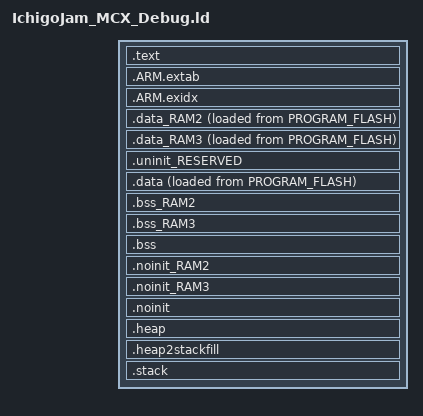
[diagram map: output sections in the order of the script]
/*
 * GENERATED FILE - DO NOT EDIT
 * Copyright 2008-2013 Code Red Technologies Ltd,
 * Copyright 2013-2025 NXP
 * SPDX-License-Identifier: BSD-3-Clause
 * Generated linker script file for MCXA153
 * Created from linkscript.ldt by FMCreateLinkLibraries
 * Using Freemarker v2.3.30
 * MCUXpresso IDE v24.12 [Build 148] [2025-01-10] on 2025/04/03 16:53:05
 */

INCLUDE "IchigoJam_MCX_Debug_library.ld"
INCLUDE "IchigoJam_MCX_Debug_memory.ld"

ENTRY(ResetISR)

SECTIONS
{
     /* MAIN TEXT SECTION */
    .text : ALIGN(4)
    {
        FILL(0xff)
        __vectors_start__ = ABSOLUTE(.) ;
        KEEP(*(.isr_vector))
        /* Global Section Table */
        . = ALIGN(4) ;
        __section_table_start = .;
        __data_section_table = .;
        LONG(LOADADDR(.data));
        LONG(    ADDR(.data));
        LONG(  SIZEOF(.data));
        LONG(LOADADDR(.data_RAM2));
        LONG(    ADDR(.data_RAM2));
        LONG(  SIZEOF(.data_RAM2));
        LONG(LOADADDR(.data_RAM3));
        LONG(    ADDR(.data_RAM3));
        LONG(  SIZEOF(.data_RAM3));
        __data_section_table_end = .;
        __bss_section_table = .;
        LONG(    ADDR(.bss));
        LONG(  SIZEOF(.bss));
        LONG(    ADDR(.bss_RAM2));
        LONG(  SIZEOF(.bss_RAM2));
        LONG(    ADDR(.bss_RAM3));
        LONG(  SIZEOF(.bss_RAM3));
        __bss_section_table_end = .;
        __section_table_end = . ;
        /* End of Global Section Table */

        *(.after_vectors*)

       *(.text*)
       *(.rodata .rodata.* .constdata .constdata.*)
       . = ALIGN(4);
    } > PROGRAM_FLASH
    /*
     * for exception handling/unwind - some Newlib functions (in common
     * with C++ and STDC++) use this.
     */
    .ARM.extab : ALIGN(4)
    {
        *(.ARM.extab* .gnu.linkonce.armextab.*)
    } > PROGRAM_FLASH

    .ARM.exidx : ALIGN(4)
    {
        __exidx_start = .;
        *(.ARM.exidx* .gnu.linkonce.armexidx.*)
        __exidx_end = .;
    } > PROGRAM_FLASH
 
    _etext = .;
        
    /* DATA section for SRAMX0 */

    .data_RAM2 : ALIGN(4)
    {
        FILL(0xff)
        PROVIDE(__start_data_RAM2 = .) ;
        PROVIDE(__start_data_SRAMX0 = .) ;
        *(.ramfunc.$RAM2)
        *(.ramfunc.$SRAMX0)
        *(.data.$RAM2)
        *(.data.$SRAMX0)
        *(.data.$RAM2.*)
        *(.data.$SRAMX0.*)
        . = ALIGN(4) ;
        PROVIDE(__end_data_RAM2 = .) ;
        PROVIDE(__end_data_SRAMX0 = .) ;
     } > SRAMX0 AT>PROGRAM_FLASH

    /* DATA section for SRAMX1 */

    .data_RAM3 : ALIGN(4)
    {
        FILL(0xff)
        PROVIDE(__start_data_RAM3 = .) ;
        PROVIDE(__start_data_SRAMX1 = .) ;
        *(.ramfunc.$RAM3)
        *(.ramfunc.$SRAMX1)
        *(.data.$RAM3)
        *(.data.$SRAMX1)
        *(.data.$RAM3.*)
        *(.data.$SRAMX1.*)
        . = ALIGN(4) ;
        PROVIDE(__end_data_RAM3 = .) ;
        PROVIDE(__end_data_SRAMX1 = .) ;
     } > SRAMX1 AT>PROGRAM_FLASH

    /* MAIN DATA SECTION */
    .uninit_RESERVED (NOLOAD) : ALIGN(4)
    {
        _start_uninit_RESERVED = .;
        KEEP(*(.bss.$RESERVED*))
       . = ALIGN(4) ;
        _end_uninit_RESERVED = .;
    } > SRAM AT> SRAM

    /* Main DATA section (SRAM) */
    .data : ALIGN(4)
    {
       FILL(0xff)
       _data = . ;
       PROVIDE(__start_data_RAM = .) ;
       PROVIDE(__start_data_SRAM = .) ;
       *(vtable)
       *(.ramfunc*)
       KEEP(*(CodeQuickAccess))
       KEEP(*(DataQuickAccess))
       *(RamFunction)
       *(.data*)
       . = ALIGN(4) ;
       _edata = . ;
       PROVIDE(__end_data_RAM = .) ;
       PROVIDE(__end_data_SRAM = .) ;
    } > SRAM AT>PROGRAM_FLASH

    /* BSS section for SRAMX0 */
    .bss_RAM2 (NOLOAD) : ALIGN(4)
    {
       PROVIDE(__start_bss_RAM2 = .) ;
       PROVIDE(__start_bss_SRAMX0 = .) ;
       *(.bss.$RAM2)
       *(.bss.$SRAMX0)
       *(.bss.$RAM2.*)
       *(.bss.$SRAMX0.*)
       . = ALIGN (. != 0 ? 4 : 1) ; /* avoid empty segment */
       PROVIDE(__end_bss_RAM2 = .) ;
       PROVIDE(__end_bss_SRAMX0 = .) ;
    } > SRAMX0 AT> SRAMX0

    /* BSS section for SRAMX1 */
    .bss_RAM3 (NOLOAD) : ALIGN(4)
    {
       PROVIDE(__start_bss_RAM3 = .) ;
       PROVIDE(__start_bss_SRAMX1 = .) ;
       *(.bss.$RAM3)
       *(.bss.$SRAMX1)
       *(.bss.$RAM3.*)
       *(.bss.$SRAMX1.*)
       . = ALIGN (. != 0 ? 4 : 1) ; /* avoid empty segment */
       PROVIDE(__end_bss_RAM3 = .) ;
       PROVIDE(__end_bss_SRAMX1 = .) ;
    } > SRAMX1 AT> SRAMX1

    /* MAIN BSS SECTION */
    .bss (NOLOAD) : ALIGN(4)
    {
        _bss = .;
        PROVIDE(__start_bss_RAM = .) ;
        PROVIDE(__start_bss_SRAM = .) ;
        *(.bss*)
        *(COMMON)
        . = ALIGN(4) ;
        _ebss = .;
        PROVIDE(__end_bss_RAM = .) ;
        PROVIDE(__end_bss_SRAM = .) ;
        PROVIDE(end = .);
    } > SRAM AT> SRAM

    /* NOINIT section for SRAMX0 */
    .noinit_RAM2 (NOLOAD) : ALIGN(4)
    {
       PROVIDE(__start_noinit_RAM2 = .) ;
       PROVIDE(__start_noinit_SRAMX0 = .) ;
       *(.noinit.$RAM2)
       *(.noinit.$SRAMX0)
       *(.noinit.$RAM2.*)
       *(.noinit.$SRAMX0.*)
       . = ALIGN(4) ;
       PROVIDE(__end_noinit_RAM2 = .) ;
       PROVIDE(__end_noinit_SRAMX0 = .) ;
    } > SRAMX0 AT> SRAMX0

    /* NOINIT section for SRAMX1 */
    .noinit_RAM3 (NOLOAD) : ALIGN(4)
    {
       PROVIDE(__start_noinit_RAM3 = .) ;
       PROVIDE(__start_noinit_SRAMX1 = .) ;
       *(.noinit.$RAM3)
       *(.noinit.$SRAMX1)
       *(.noinit.$RAM3.*)
       *(.noinit.$SRAMX1.*)
       . = ALIGN(4) ;
       PROVIDE(__end_noinit_RAM3 = .) ;
       PROVIDE(__end_noinit_SRAMX1 = .) ;
    } > SRAMX1 AT> SRAMX1

    /* DEFAULT NOINIT SECTION */
    .noinit (NOLOAD): ALIGN(4)
    {
        _noinit = .;
        PROVIDE(__start_noinit_RAM = .) ;
        PROVIDE(__start_noinit_SRAM = .) ;
        *(.noinit*)
         . = ALIGN(4) ;
        _end_noinit = .;
       PROVIDE(__end_noinit_RAM = .) ;
       PROVIDE(__end_noinit_SRAM = .) ;        
    } > SRAM AT> SRAM

    /* Reserve and place Heap within memory map */
    _HeapSize = 0x600;
    .heap (NOLOAD) :  ALIGN(4)
    {
        _pvHeapStart = .;
        . += _HeapSize;
        . = ALIGN(4);
        _pvHeapLimit = .;
    } > SRAM

     _StackSize = 0x600;
     /* Reserve space in memory for Stack */
    .heap2stackfill (NOLOAD) :
    {
        . += _StackSize;
    } > SRAM
    /* Locate actual Stack in memory map */
    .stack ORIGIN(SRAM) + LENGTH(SRAM) - _StackSize - 0 (NOLOAD) :  ALIGN(4)
    {
        _vStackBase = .;
        . = ALIGN(4);
        _vStackTop = . + _StackSize;
    } > SRAM

    /* Provide basic symbols giving location and size of main text
     * block, including initial values of RW data sections. Note that
     * these will need extending to give a complete picture with
     * complex images (e.g multiple Flash banks).
     */
    _image_start = LOADADDR(.text);
    _image_end = LOADADDR(.data) + SIZEOF(.data);
    _image_size = _image_end - _image_start;
}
